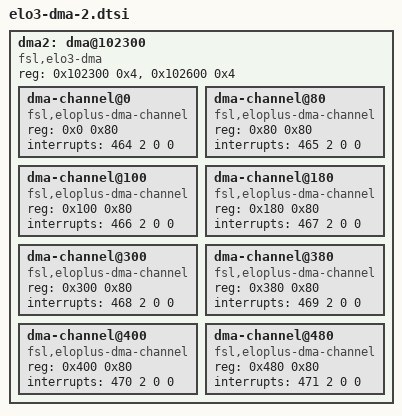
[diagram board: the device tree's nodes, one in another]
dma2: dma@102300 {
	#address-cells = <1>;
	#size-cells = <1>;
	compatible = "fsl,elo3-dma";
	reg = <0x102300 0x4>,
	      <0x102600 0x4>;
	ranges = <0x0 0x102100 0x500>;
	dma-channel@0 {
		compatible = "fsl,eloplus-dma-channel";
		reg = <0x0 0x80>;
		interrupts = <464 2 0 0>;
	};
	dma-channel@80 {
		compatible = "fsl,eloplus-dma-channel";
		reg = <0x80 0x80>;
		interrupts = <465 2 0 0>;
	};
	dma-channel@100 {
		compatible = "fsl,eloplus-dma-channel";
		reg = <0x100 0x80>;
		interrupts = <466 2 0 0>;
	};
	dma-channel@180 {
		compatible = "fsl,eloplus-dma-channel";
		reg = <0x180 0x80>;
		interrupts = <467 2 0 0>;
	};
	dma-channel@300 {
		compatible = "fsl,eloplus-dma-channel";
		reg = <0x300 0x80>;
		interrupts = <468 2 0 0>;
	};
	dma-channel@380 {
		compatible = "fsl,eloplus-dma-channel";
		reg = <0x380 0x80>;
		interrupts = <469 2 0 0>;
	};
	dma-channel@400 {
		compatible = "fsl,eloplus-dma-channel";
		reg = <0x400 0x80>;
		interrupts = <470 2 0 0>;
	};
	dma-channel@480 {
		compatible = "fsl,eloplus-dma-channel";
		reg = <0x480 0x80>;
		interrupts = <471 2 0 0>;
	};
};
